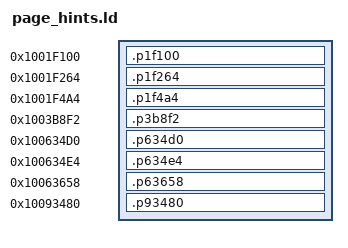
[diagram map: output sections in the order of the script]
SECTIONS {
.p1f100 0x1001f100 : { *(.p1f100) }
.p1f264 0x1001f264 : { *(.p1f264) }
.p1f4a4 0x1001f4a4 : { *(.p1f4a4) }
.p3b8f2 0x1003b8f2 : { *(.p3b8f2) }
.p634d0 0x100634d0 : { *(.p634d0) }
.p634e4 0x100634e4 : { *(.p634e4) }
.p63658 0x10063658 : { *(.p63658) }
.p93480 0x10093480 : { *(.p93480) }
}
allocate = 0x100121c9;
object_destroy = 0x10008e65;
object_create = 0x10057021;
widget_layer = 0x100078e9;
set_position = 0x10041cd1;
sprite_create = 0x10057771;
indexed_sprite_create = 0x1005783d;
